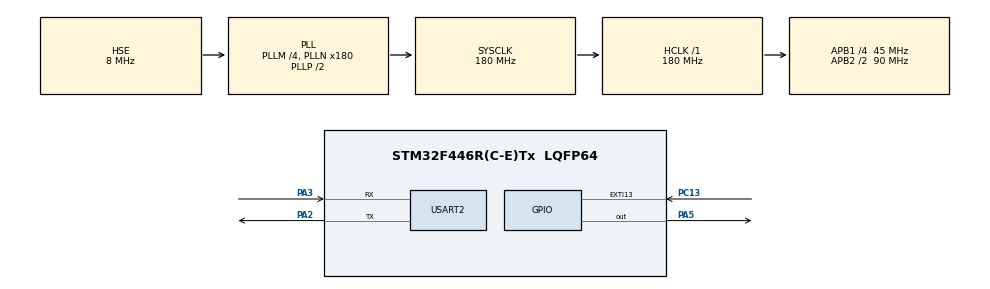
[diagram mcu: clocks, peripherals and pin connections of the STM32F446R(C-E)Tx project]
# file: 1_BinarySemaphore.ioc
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FREERTOS.BinarySemaphores01=BinarySem01,Dynamic,NULL,Available
FREERTOS.Tasks01=Task01,32,128,Task01_Entry,Default,NULL,Dynamic,NULL,NULL;Task02,24,128,Task02_Entry,Default,NULL,Dynamic,NULL,NULL
FREERTOS.configUSE_NEWLIB_REENTRANT=1
Mcu.Family=STM32F4
Mcu.Name=STM32F446R(C-E)Tx
Mcu.Package=LQFP64
NVIC.EXTI15_10_IRQn=true\:5\:0\:false\:false\:true\:true\:true\:true\:true
NVIC.PriorityGroup=NVIC_PRIORITYGROUP_4
NVIC.TIM6_DAC_IRQn=true\:15\:0\:false\:false\:true\:false\:false\:true\:true
NVIC.TimeBase=TIM6_DAC_IRQn
NVIC.TimeBaseIP=TIM6
PA2.Mode=Asynchronous
PA2.Signal=USART2_TX
PA3.Mode=Asynchronous
PA3.Signal=USART2_RX
PA5.Signal=GPIO_Output
PC13.GPIO_ModeDefaultEXTI=GPIO_MODE_IT_FALLING
PC13.Signal=GPXTI13
PH0-OSC_IN.Mode=HSE-External-Oscillator
PH0-OSC_IN.Signal=RCC_OSC_IN
PH1-OSC_OUT.Mode=HSE-External-Oscillator
PH1-OSC_OUT.Signal=RCC_OSC_OUT
ProjectManager.HeapSize=0x200
ProjectManager.StackSize=0x400
ProjectManager.TargetToolchain=STM32CubeIDE
RCC.AHBFreq_Value=180000000
RCC.APB1CLKDivider=RCC_HCLK_DIV4
RCC.APB1Freq_Value=45000000
RCC.APB1TimFreq_Value=90000000
RCC.APB2CLKDivider=RCC_HCLK_DIV2
RCC.APB2Freq_Value=90000000
RCC.APB2TimFreq_Value=180000000
RCC.CortexFreq_Value=180000000
RCC.FLatency-AdvancedSettings=FLASH_LATENCY_5
RCC.HCLKFreq_Value=180000000
RCC.HSE_VALUE=8000000
RCC.HSI_VALUE=16000000
RCC.LSE_VALUE=32768
RCC.PLLM=4
RCC.PLLN=180
RCC.PLLSourceVirtual=RCC_PLLSOURCE_HSE
RCC.SYSCLKFreq_VALUE=180000000
RCC.SYSCLKSource=RCC_SYSCLKSOURCE_PLLCLK
RCC.USBFreq_Value=180000000
RCC.VCOOutputFreq_Value=360000000
USART2.VirtualMode=VM_ASYNC
VP_FREERTOS_VS_CMSIS_V2.Mode=CMSIS_V2
VP_SYS_VS_tim6.Mode=TIM6
board=NUCLEO-F446RE

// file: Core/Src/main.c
/* USER CODE BEGIN Header */
/**
  ******************************************************************************
  * @file           : main.c
  * @brief          : Main program body
  ******************************************************************************
  * @attention
  *
  * Copyright (c) 2026 STMicroelectronics.
  * All rights reserved.
  *
  * This software is licensed under terms that can be found in the LICENSE file
  * in the root directory of this software component.
  * If no LICENSE file comes with this software, it is provided AS-IS.
  *
  ******************************************************************************
  */
/* USER CODE END Header */
#include "main.h"
#include "cmsis_os.h"

UART_HandleTypeDef huart2;

/* Definitions for Task01 */
osThreadId_t Task01Handle;
const osThreadAttr_t Task01_attributes = {
  .name = "Task01",
  .stack_size = 128 * 4,
  .priority = (osPriority_t) osPriorityAboveNormal,
};
/* Definitions for Task02 */
osThreadId_t Task02Handle;
const osThreadAttr_t Task02_attributes = {
  .name = "Task02",
  .stack_size = 128 * 4,
  .priority = (osPriority_t) osPriorityNormal,
};
/* Definitions for BinarySem01 */
osSemaphoreId_t BinarySem01Handle;
const osSemaphoreAttr_t BinarySem01_attributes = {
  .name = "BinarySem01"
};

void SystemClock_Config(void);
static void MX_GPIO_Init(void);
static void MX_USART2_UART_Init(void);
void Task01_Entry(void *argument);
void Task02_Entry(void *argument);

int main(void)
{

  /* MCU Configuration--------------------------------------------------------*/

  /* Reset of all peripherals, Initializes the Flash interface and the Systick. */
  HAL_Init();

  /* Configure the system clock */
  SystemClock_Config();

  /* Initialize all configured peripherals */
  MX_GPIO_Init();
  MX_USART2_UART_Init();

  /* Init scheduler */
  osKernelInitialize();

  /* Create the semaphores(s) */
  /* creation of BinarySem01 */
  BinarySem01Handle = osSemaphoreNew(1, 1, &BinarySem01_attributes);

  /* Create the thread(s) */
  /* creation of Task01 */
  Task01Handle = osThreadNew(Task01_Entry, NULL, &Task01_attributes);

  /* creation of Task02 */
  Task02Handle = osThreadNew(Task02_Entry, NULL, &Task02_attributes);

  /* Start scheduler */
  osKernelStart();

  /* We should never get here as control is now taken by the scheduler */

  /* Infinite loop */
  while (1)
  {

  }
}

void SystemClock_Config(void)
{
  RCC_OscInitTypeDef RCC_OscInitStruct = {0};
  RCC_ClkInitTypeDef RCC_ClkInitStruct = {0};

  /** Configure the main internal regulator output voltage
  */
  __HAL_RCC_PWR_CLK_ENABLE();
  __HAL_PWR_VOLTAGESCALING_CONFIG(PWR_REGULATOR_VOLTAGE_SCALE1);

  /** Initializes the RCC Oscillators according to the specified parameters
  * in the RCC_OscInitTypeDef structure.
  */
  RCC_OscInitStruct.OscillatorType = RCC_OSCILLATORTYPE_HSE;
  RCC_OscInitStruct.HSEState = RCC_HSE_ON;
  RCC_OscInitStruct.PLL.PLLState = RCC_PLL_ON;
  RCC_OscInitStruct.PLL.PLLSource = RCC_PLLSOURCE_HSE;
  RCC_OscInitStruct.PLL.PLLM = 4;
  RCC_OscInitStruct.PLL.PLLN = 180;
  RCC_OscInitStruct.PLL.PLLP = RCC_PLLP_DIV2;
  RCC_OscInitStruct.PLL.PLLQ = 2;
  RCC_OscInitStruct.PLL.PLLR = 2;
  if (HAL_RCC_OscConfig(&RCC_OscInitStruct) != HAL_OK)
  {
    Error_Handler();
  }

  /** Activate the Over-Drive mode
  */
  if (HAL_PWREx_EnableOverDrive() != HAL_OK)
  {
    Error_Handler();
  }

  /** Initializes the CPU, AHB and APB buses clocks
  */
  RCC_ClkInitStruct.ClockType = RCC_CLOCKTYPE_HCLK|RCC_CLOCKTYPE_SYSCLK
                              |RCC_CLOCKTYPE_PCLK1|RCC_CLOCKTYPE_PCLK2;
  RCC_ClkInitStruct.SYSCLKSource = RCC_SYSCLKSOURCE_PLLCLK;
  RCC_ClkInitStruct.AHBCLKDivider = RCC_SYSCLK_DIV1;
  RCC_ClkInitStruct.APB1CLKDivider = RCC_HCLK_DIV4;
  RCC_ClkInitStruct.APB2CLKDivider = RCC_HCLK_DIV2;

  if (HAL_RCC_ClockConfig(&RCC_ClkInitStruct, FLASH_LATENCY_5) != HAL_OK)
  {
    Error_Handler();
  }
}

static void MX_USART2_UART_Init(void)
{

  huart2.Instance = USART2;
  huart2.Init.BaudRate = 115200;
  huart2.Init.WordLength = UART_WORDLENGTH_8B;
  huart2.Init.StopBits = UART_STOPBITS_1;
  huart2.Init.Parity = UART_PARITY_NONE;
  huart2.Init.Mode = UART_MODE_TX_RX;
  huart2.Init.HwFlowCtl = UART_HWCONTROL_NONE;
  huart2.Init.OverSampling = UART_OVERSAMPLING_16;
  if (HAL_UART_Init(&huart2) != HAL_OK)
  {
    Error_Handler();
  }

}

static void MX_GPIO_Init(void)
{
  GPIO_InitTypeDef GPIO_InitStruct = {0};

  /* GPIO Ports Clock Enable */
  __HAL_RCC_GPIOC_CLK_ENABLE();
  __HAL_RCC_GPIOH_CLK_ENABLE();
  __HAL_RCC_GPIOA_CLK_ENABLE();

  /*Configure GPIO pin Output Level */
  HAL_GPIO_WritePin(GPIOA, GPIO_PIN_5, GPIO_PIN_RESET);

  /*Configure GPIO pin : PC13 */
  GPIO_InitStruct.Pin = GPIO_PIN_13;
  GPIO_InitStruct.Mode = GPIO_MODE_IT_FALLING;
  GPIO_InitStruct.Pull = GPIO_NOPULL;
  HAL_GPIO_Init(GPIOC, &GPIO_InitStruct);

  /*Configure GPIO pin : PA5 */
  GPIO_InitStruct.Pin = GPIO_PIN_5;
  GPIO_InitStruct.Mode = GPIO_MODE_OUTPUT_PP;
  GPIO_InitStruct.Pull = GPIO_NOPULL;
  GPIO_InitStruct.Speed = GPIO_SPEED_FREQ_LOW;
  HAL_GPIO_Init(GPIOA, &GPIO_InitStruct);

  /* EXTI interrupt init*/
  HAL_NVIC_SetPriority(EXTI15_10_IRQn, 5, 0);
  HAL_NVIC_EnableIRQ(EXTI15_10_IRQn);

}

/* USER CODE BEGIN 4 */
void HAL_GPIO_EXTI_Callback(uint16_t GPIO_Pin){
	if(GPIO_Pin == GPIO_PIN_13){
//		release the semaphore
		HAL_GPIO_TogglePin(GPIOA, GPIO_PIN_5);

//		BaseType_t xHigherPriorityTaskWoken = pdFALSE;
//		xSemaphoreGiveFromISR( BinarySem01Handle, &xHigherPriorityTaskWoken );
//		portYIELD_FROM_ISR( xHigherPriorityTaskWoken ); //context switch immediately if HigherPrio

//		or

		osSemaphoreRelease(BinarySem01Handle);
	}
}
/* USER CODE END 4 */

void Task01_Entry(void *argument)
{
  /* USER CODE BEGIN 5 */
  /* Infinite loop */
  for(;;)
  {
	  osSemaphoreAcquire(BinarySem01Handle, osWaitForever);
	  HAL_UART_Transmit(&huart2, (uint8_t *)"Running Task 1\r\n",16, 10);
	  osDelay(3000);
  }
  /* USER CODE END 5 */
}

void Task02_Entry(void *argument)
{
  /* USER CODE BEGIN Task02_Entry */
  /* Infinite loop */
  for(;;)
  {
	  osSemaphoreAcquire(BinarySem01Handle, osWaitForever);
	  HAL_UART_Transmit(&huart2, (uint8_t *)"Running Task 2\r\n",16, 10);
	  osDelay(1000);
  }
  /* USER CODE END Task02_Entry */
}

void HAL_TIM_PeriodElapsedCallback(TIM_HandleTypeDef *htim)
{
  if (htim->Instance == TIM6) {
    HAL_IncTick();
  }
}

void Error_Handler(void)
{
  __disable_irq();
  while (1)
  {
  }
}
